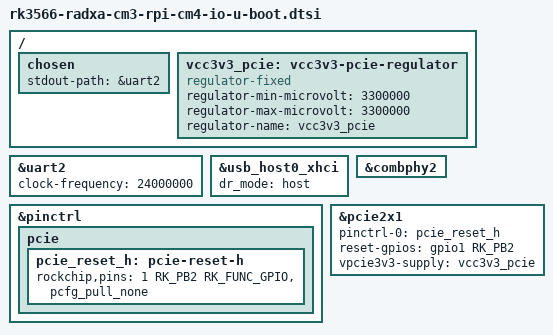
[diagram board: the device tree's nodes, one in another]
// SPDX-License-Identifier: GPL-2.0+
/*
 * (C) Copyright 2021 Rockchip Electronics Co., Ltd
 */

#include "rk356x-u-boot.dtsi"

/ {
	chosen {
		stdout-path = &uart2;
	};

	vcc3v3_pcie: vcc3v3-pcie-regulator {
		compatible = "regulator-fixed";
		regulator-min-microvolt = <3300000>;
		regulator-max-microvolt = <3300000>;
		regulator-name = "vcc3v3_pcie";
	};
};

&uart2 {
	clock-frequency = <24000000>;
	bootph-all;
	status = "okay";
};

&usb_host0_xhci {
	dr_mode ="host";
};

&combphy2 {
	status = "okay";
};

&pinctrl {
	pcie {
		pcie_reset_h: pcie-reset-h {
			rockchip,pins = <1 RK_PB2 RK_FUNC_GPIO &pcfg_pull_none>;
		};
	};
};

&pcie2x1 {
	pinctrl-names = "default";
	pinctrl-0 = <&pcie_reset_h>;
	reset-gpios = <&gpio1 RK_PB2 GPIO_ACTIVE_HIGH>;
	vpcie3v3-supply = <&vcc3v3_pcie>;
	status = "okay";
};
